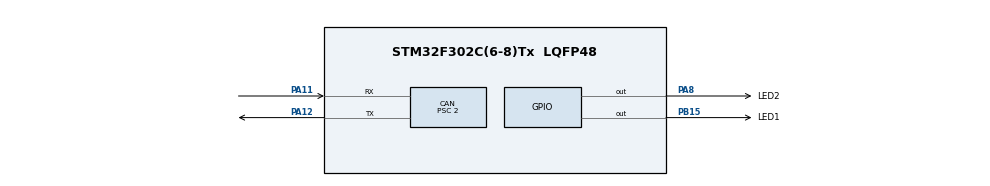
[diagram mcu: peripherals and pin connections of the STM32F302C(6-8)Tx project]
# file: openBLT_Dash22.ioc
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CAN.ABOM=ENABLE
CAN.BS1=CAN_BS1_15TQ
CAN.BS2=CAN_BS2_2TQ
CAN.CalculateBaudRate=1000000
CAN.CalculateTimeBit=1000
CAN.CalculateTimeQuantum=55.55555555555556
CAN.Prescaler=2
CAN.SJW=CAN_SJW_1TQ
Mcu.Family=STM32F3
Mcu.Name=STM32F302C(6-8)Tx
Mcu.Package=LQFP48
NVIC.CAN_RX1_IRQn=true\:0\:0\:false\:false\:true\:true\:true\:true
NVIC.CAN_SCE_IRQn=true\:0\:0\:false\:false\:true\:true\:true\:true
NVIC.PriorityGroup=NVIC_PRIORITYGROUP_4
NVIC.USB_LP_CAN_RX0_IRQn=true\:0\:0\:false\:false\:true\:true\:true\:true
PA11.Mode=CAN_Activate
PA11.Signal=CAN_RX
PA12.Mode=CAN_Activate
PA12.Signal=CAN_TX
PA13.Mode=Serial_Wire
PA13.Signal=SYS_JTMS-SWDIO
PA14.Mode=Serial_Wire
PA14.Signal=SYS_JTCK-SWCLK
PA8.GPIO_Label=LED2
PA8.GPIO_PuPd=GPIO_PULLDOWN
PA8.PinState=GPIO_PIN_SET
PA8.Signal=GPIO_Output
PB15.GPIO_Label=LED1
PB15.Signal=GPIO_Output
PF0-OSC_IN.Mode=HSE-External-Oscillator
PF0-OSC_IN.Signal=RCC_OSC_IN
PF1-OSC_OUT.Mode=HSE-External-Oscillator
PF1-OSC_OUT.Signal=RCC_OSC_OUT
ProjectManager.HeapSize=0x200
ProjectManager.StackSize=0x400
ProjectManager.TargetToolchain=Makefile
RCC.AHBFreq_Value=72000000
RCC.APB1CLKDivider=RCC_HCLK_DIV2
RCC.APB1Freq_Value=36000000
RCC.APB1TimFreq_Value=72000000
RCC.APB2Freq_Value=72000000
RCC.APB2TimFreq_Value=72000000
RCC.CortexFreq_Value=72000000
RCC.DATA_CACHE_ENABLE=1
RCC.HCLKFreq_Value=72000000
RCC.HSE_VALUE=8000000
RCC.HSI_VALUE=8000000
RCC.INSTRUCTION_CACHE_ENABLE=1
RCC.LSE_VALUE=32768
RCC.PLLMUL=RCC_PLL_MUL9
RCC.PLLSourceVirtual=RCC_PLLSOURCE_HSE
RCC.PWR_Regulator_Voltage_Scale=PWR_REGULATOR_VOLTAGE_SCALE2
RCC.RCC_TIM_PRescaler_Selection=RCC_TIMPRES_DESACTIVATED
RCC.SYSCLKFreq_VALUE=72000000
RCC.SYSCLKSourceVirtual=RCC_SYSCLKSOURCE_PLLCLK
RCC.USBFreq_Value=72000000
board=custom

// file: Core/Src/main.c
/* USER CODE BEGIN Header */
/**
  ******************************************************************************
  * @file           : main.c
  * @brief          : Main program body
  ******************************************************************************
  * @attention
  *
  * Copyright (c) 2022 STMicroelectronics.
  * All rights reserved.
  *
  * This software is licensed under terms that can be found in the LICENSE file
  * in the root directory of this software component.
  * If no LICENSE file comes with this software, it is provided AS-IS.
  *
  ******************************************************************************
  */
/* USER CODE END Header */
#include "main.h"

/* USER CODE BEGIN Includes */
#include <stdint.h>
#include "BLT/boot.h"
/* USER CODE END Includes */

CAN_HandleTypeDef hcan;

void SystemClock_Config(void);
static void MX_GPIO_Init(void);
static void MX_CAN_Init(void);

int main(void)
{

  /* MCU Configuration--------------------------------------------------------*/

  /* Reset of all peripherals, Initializes the Flash interface and the Systick. */
  HAL_Init();

  /* Configure the system clock */
  SystemClock_Config();

  /* Initialize all configured peripherals */
  MX_GPIO_Init();
  MX_CAN_Init();
  /* USER CODE BEGIN 2 */
  BootInit();
  /* USER CODE END 2 */

  /* Infinite loop */
  /* USER CODE BEGIN WHILE */
  while (1)
  {
	BootTask();
    /* USER CODE END WHILE */

  }
}

void SystemClock_Config(void)
{
  LL_FLASH_SetLatency(LL_FLASH_LATENCY_2);
  while(LL_FLASH_GetLatency()!= LL_FLASH_LATENCY_2)
  {
  }
  LL_RCC_HSE_Enable();

   /* Wait till HSE is ready */
  while(LL_RCC_HSE_IsReady() != 1)
  {

  }
  LL_RCC_PLL_ConfigDomain_SYS(LL_RCC_PLLSOURCE_HSE_DIV_1, LL_RCC_PLL_MUL_9);
  LL_RCC_PLL_Enable();

   /* Wait till PLL is ready */
  while(LL_RCC_PLL_IsReady() != 1)
  {

  }
  LL_RCC_SetAHBPrescaler(LL_RCC_SYSCLK_DIV_1);
  LL_RCC_SetAPB1Prescaler(LL_RCC_APB1_DIV_2);
  LL_RCC_SetAPB2Prescaler(LL_RCC_APB2_DIV_1);
  LL_RCC_SetSysClkSource(LL_RCC_SYS_CLKSOURCE_PLL);

   /* Wait till System clock is ready */
  while(LL_RCC_GetSysClkSource() != LL_RCC_SYS_CLKSOURCE_STATUS_PLL)
  {

  }
  LL_SetSystemCoreClock(72000000);

   /* Update the time base */
  if (HAL_InitTick (TICK_INT_PRIORITY) != HAL_OK)
  {
    Error_Handler();
  }
}

static void MX_CAN_Init(void)
{

  hcan.Instance = CAN;
  hcan.Init.Prescaler = 2;
  hcan.Init.Mode = CAN_MODE_NORMAL;
  hcan.Init.SyncJumpWidth = CAN_SJW_1TQ;
  hcan.Init.TimeSeg1 = CAN_BS1_15TQ;
  hcan.Init.TimeSeg2 = CAN_BS2_2TQ;
  hcan.Init.TimeTriggeredMode = DISABLE;
  hcan.Init.AutoBusOff = ENABLE;
  hcan.Init.AutoWakeUp = DISABLE;
  hcan.Init.AutoRetransmission = DISABLE;
  hcan.Init.ReceiveFifoLocked = DISABLE;
  hcan.Init.TransmitFifoPriority = DISABLE;
  if (HAL_CAN_Init(&hcan) != HAL_OK)
  {
    Error_Handler();
  }

}

static void MX_GPIO_Init(void)
{
  GPIO_InitTypeDef GPIO_InitStruct = {0};

  /* GPIO Ports Clock Enable */
  __HAL_RCC_GPIOF_CLK_ENABLE();
  __HAL_RCC_GPIOB_CLK_ENABLE();
  __HAL_RCC_GPIOA_CLK_ENABLE();

  /*Configure GPIO pin Output Level */
  HAL_GPIO_WritePin(LED1_GPIO_Port, LED1_Pin, GPIO_PIN_RESET);

  /*Configure GPIO pin Output Level */
  HAL_GPIO_WritePin(LED2_GPIO_Port, LED2_Pin, GPIO_PIN_SET);

  /*Configure GPIO pin : LED1_Pin */
  GPIO_InitStruct.Pin = LED1_Pin;
  GPIO_InitStruct.Mode = GPIO_MODE_OUTPUT_PP;
  GPIO_InitStruct.Pull = GPIO_NOPULL;
  GPIO_InitStruct.Speed = GPIO_SPEED_FREQ_LOW;
  HAL_GPIO_Init(LED1_GPIO_Port, &GPIO_InitStruct);

  /*Configure GPIO pin : LED2_Pin */
  GPIO_InitStruct.Pin = LED2_Pin;
  GPIO_InitStruct.Mode = GPIO_MODE_OUTPUT_PP;
  GPIO_InitStruct.Pull = GPIO_PULLDOWN;
  GPIO_InitStruct.Speed = GPIO_SPEED_FREQ_LOW;
  HAL_GPIO_Init(LED2_GPIO_Port, &GPIO_InitStruct);

}

void Error_Handler(void)
{
  __disable_irq();
  while (1)
  {
  }
}
